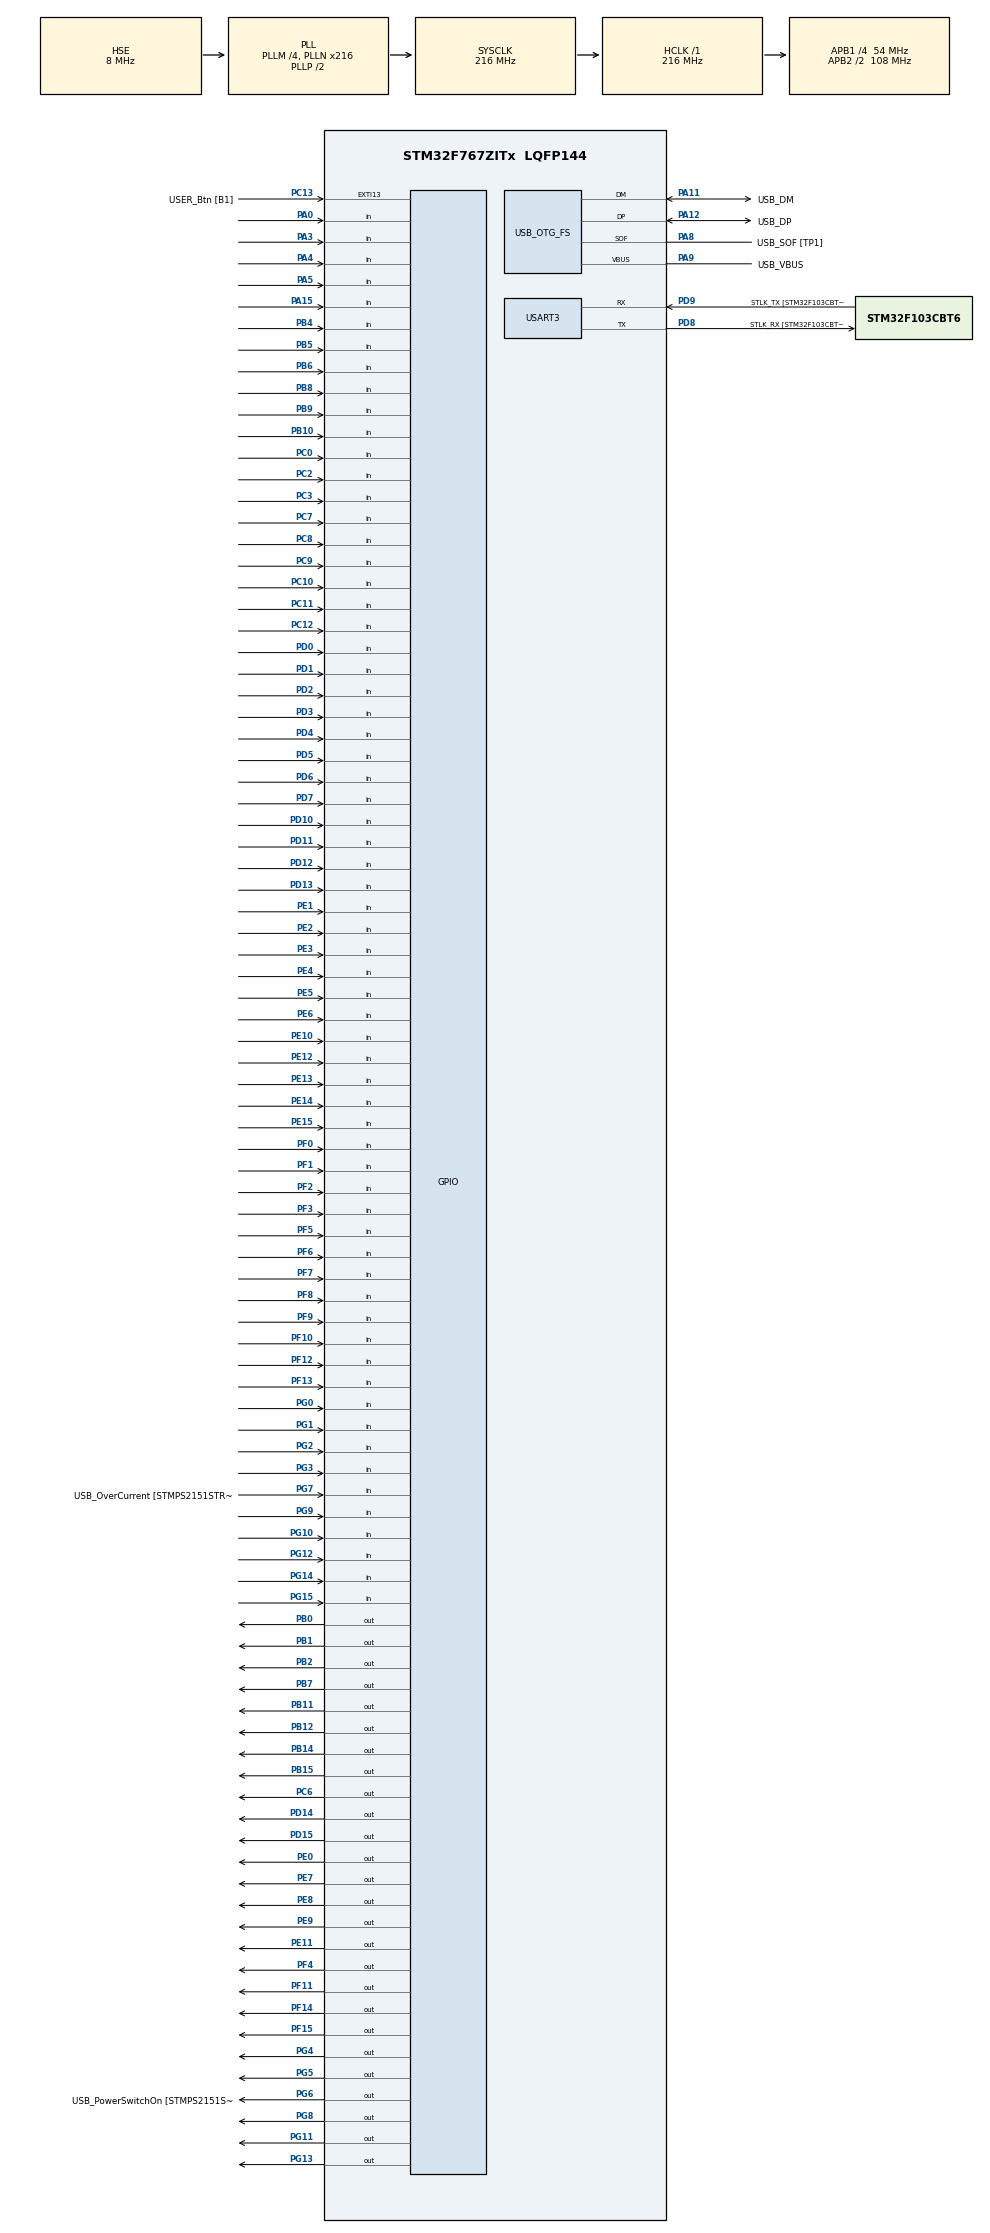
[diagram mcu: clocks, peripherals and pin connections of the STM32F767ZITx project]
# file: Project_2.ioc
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Mcu.Family=STM32F7
Mcu.Name=STM32F767ZITx
Mcu.Package=LQFP144
NVIC.PriorityGroup=NVIC_PRIORITYGROUP_2
NVIC.TIM3_IRQn=true\:1\:0\:true\:false\:true\:true\:true\:true
NVIC.TIM4_IRQn=true\:1\:0\:true\:false\:true\:true\:true\:true
PA0/WKUP.Signal=GPIO_Input
PA10.GPIO_Label=USB_ID
PA10.Signal=USB_OTG_FS_ID
PA11.GPIO_Label=USB_DM
PA11.Mode=Device_Only
PA11.Signal=USB_OTG_FS_DM
PA12.GPIO_Label=USB_DP
PA12.Mode=Device_Only
PA12.Signal=USB_OTG_FS_DP
PA13.GPIO_Label=TMS
PA13.Mode=Serial_Wire
PA13.Signal=SYS_JTMS-SWDIO
PA14.GPIO_Label=TCK
PA14.Mode=Serial_Wire
PA14.Signal=SYS_JTCK-SWCLK
PA15.Signal=GPIO_Input
PA3.Signal=GPIO_Input
PA4.Signal=GPIO_Input
PA5.Signal=GPIO_Input
PA8.GPIO_Label=USB_SOF [TP1]
PA8.Mode=Activate_SOF_FS
PA8.Signal=USB_OTG_FS_SOF
PA9.GPIO_Label=USB_VBUS
PA9.Mode=Activate_VBUS
PA9.Signal=USB_OTG_FS_VBUS
PB0.Signal=GPIO_Output
PB1.Signal=GPIO_Output
PB10.Signal=GPIO_Input
PB11.Signal=GPIO_Output
PB12.Signal=GPIO_Output
PB14.Signal=GPIO_Output
PB15.Signal=GPIO_Output
PB2.Signal=GPIO_Output
PB3.GPIO_Label=SWO
PB3.Signal=SYS_JTDO-SWO
PB4.Signal=GPIO_Input
PB5.Signal=GPIO_Input
PB6.Signal=GPIO_Input
PB7.Signal=GPIO_Output
PB8.Signal=GPIO_Input
PB9.Signal=GPIO_Input
PC0.Signal=GPIO_Input
PC10.Signal=GPIO_Input
PC11.Signal=GPIO_Input
PC12.Signal=GPIO_Input
PC13.GPIO_Label=USER_Btn [B1]
PC13.Signal=GPXTI13
PC14/OSC32_IN.Mode=LSE-External-Oscillator
PC14/OSC32_IN.Signal=RCC_OSC32_IN
PC15/OSC32_OUT.Mode=LSE-External-Oscillator
PC15/OSC32_OUT.Signal=RCC_OSC32_OUT
PC2.Signal=GPIO_Input
PC3.Signal=GPIO_Input
PC6.Signal=GPIO_Output
PC7.Signal=GPIO_Input
PC8.Signal=GPIO_Input
PC9.Signal=GPIO_Input
PD0.Signal=GPIO_Input
PD1.Signal=GPIO_Input
PD10.Signal=GPIO_Input
PD11.Signal=GPIO_Input
PD12.Signal=GPIO_Input
PD13.Signal=GPIO_Input
PD14.Signal=GPIO_Output
PD15.Signal=GPIO_Output
PD2.Signal=GPIO_Input
PD3.Signal=GPIO_Input
PD4.Signal=GPIO_Input
PD5.Signal=GPIO_Input
PD6.Signal=GPIO_Input
PD7.Signal=GPIO_Input
PD8.GPIO_Label=STLK_RX [STM32F103CBT6_PA3]
PD8.Mode=Asynchronous
PD8.Signal=USART3_TX
PD9.GPIO_Label=STLK_TX [STM32F103CBT6_PA2]
PD9.Mode=Asynchronous
PD9.Signal=USART3_RX
PE0.Signal=GPIO_Output
PE1.Signal=GPIO_Input
PE10.Signal=GPIO_Input
PE11.Signal=GPIO_Output
PE12.Signal=GPIO_Input
PE13.Signal=GPIO_Input
PE14.Signal=GPIO_Input
PE15.Signal=GPIO_Input
PE2.Signal=GPIO_Input
PE3.Signal=GPIO_Input
PE4.Signal=GPIO_Input
PE5.Signal=GPIO_Input
PE6.Signal=GPIO_Input
PE7.Signal=GPIO_Output
PE8.Signal=GPIO_Output
PE9.Signal=GPIO_Output
PF0.Signal=GPIO_Input
PF1.Signal=GPIO_Input
PF10.Signal=GPIO_Input
PF11.Signal=GPIO_Output
PF12.Signal=GPIO_Input
PF13.Signal=GPIO_Input
PF14.Signal=GPIO_Output
PF15.Signal=GPIO_Output
PF2.Signal=GPIO_Input
PF3.Signal=GPIO_Input
PF4.Signal=GPIO_Output
PF5.Signal=GPIO_Input
PF6.Signal=GPIO_Input
PF7.Signal=GPIO_Input
PF8.Signal=GPIO_Input
PF9.Signal=GPIO_Input
PG0.Signal=GPIO_Input
PG1.Signal=GPIO_Input
PG10.Signal=GPIO_Input
PG11.Signal=GPIO_Output
PG12.Signal=GPIO_Input
PG13.Signal=GPIO_Output
PG14.Signal=GPIO_Input
PG15.Signal=GPIO_Input
PG2.Signal=GPIO_Input
PG3.Signal=GPIO_Input
PG4.Signal=GPIO_Output
PG5.Signal=GPIO_Output
PG6.GPIO_Label=USB_PowerSwitchOn [STMPS2151STR_EN]
PG6.Signal=GPIO_Output
PG7.GPIO_Label=USB_OverCurrent [STMPS2151STR_FAULT]
PG7.Signal=GPIO_Input
PG8.Signal=GPIO_Output
PG9.Signal=GPIO_Input
PH0/OSC_IN.GPIO_Label=MCO [STM32F103CBT6_PA8]
PH0/OSC_IN.Mode=HSE-External-Clock-Source
PH0/OSC_IN.Signal=RCC_OSC_IN
PH1/OSC_OUT.Mode=HSE-External-Clock-Source
PH1/OSC_OUT.Signal=RCC_OSC_OUT
ProjectManager.HeapSize=0x200
ProjectManager.StackSize=0x400
ProjectManager.TargetToolchain=STM32CubeIDE
RCC.48MHZClocksFreq_Value=24000000
RCC.AHBFreq_Value=216000000
RCC.APB1CLKDivider=RCC_HCLK_DIV4
RCC.APB1Freq_Value=54000000
RCC.APB1TimFreq_Value=108000000
RCC.APB2CLKDivider=RCC_HCLK_DIV2
RCC.APB2Freq_Value=108000000
RCC.APB2TimFreq_Value=216000000
RCC.CortexFreq_Value=216000000
RCC.HCLKFreq_Value=216000000
RCC.HSE_VALUE=8000000
RCC.HSI_VALUE=16000000
RCC.PLLM=4
RCC.PLLMUL=RCC_PLL_MUL9
RCC.PLLN=216
RCC.PLLQ=9
RCC.PRESCALERUSB=RCC_USBCLKSOURCE_PLL_DIV1_5
RCC.SYSCLKFreq_VALUE=216000000
RCC.SYSCLKSource=RCC_SYSCLKSOURCE_PLLCLK
RCC.SYSCLKSourceVirtual=RCC_SYSCLKSOURCE_PLLCLK
RCC.USBFreq_Value=48000000
RCC.VCOOutputFreq_Value=432000000
TIM3.Period=10000-1
TIM3.Prescaler=6480-1
TIM4.Period=10000-1
TIM4.Prescaler=5400-1
USART3.VirtualMode-Asynchronous=VM_ASYNC
USB_OTG_FS.VirtualMode=Device_Only
VP_TIM3_VS_ClockSourceINT.Mode=Internal
VP_TIM4_VS_ClockSourceINT.Mode=Internal
board=NUCLEO-F767ZI

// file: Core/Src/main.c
/* USER CODE BEGIN Header */
/**
  ******************************************************************************
  * @file           : main.c
  * @brief          : Main program body
  ******************************************************************************
  * @attention
  *
  * Copyright (c) 2022 STMicroelectronics.
  * All rights reserved.
  *
  * This software is licensed under terms that can be found in the LICENSE file
  * in the root directory of this software component.
  * If no LICENSE file comes with this software, it is provided AS-IS.
  *
  ******************************************************************************
  */
/* USER CODE END Header */
#include "main.h"

/* USER CODE BEGIN Includes */
#include "stdio.h"
#include <stdbool.h>
/* USER CODE END Includes */

/* USER CODE BEGIN PD */
#define true 	1
#define false  	0

uint32_t CountTim4; 				//For Scan Board
uint32_t CountTim3_PrintCheck;		//Print Debug
//bool a4;
//bool a3;
//bool a2;
//bool a1;
//extern bool OldState[8][8];
//bool NewState[8][8];
//extern bool State[8][8];
//char str[100];

/* USER CODE END PD */

TIM_HandleTypeDef htim3;
TIM_HandleTypeDef htim4;

UART_HandleTypeDef huart3;

PCD_HandleTypeDef hpcd_USB_OTG_FS;

void SystemClock_Config(void);
static void MX_GPIO_Init(void);
static void MX_USART3_UART_Init(void);
static void MX_USB_OTG_FS_PCD_Init(void);
static void MX_TIM4_Init(void);
static void MX_TIM3_Init(void);

int main(void)
{
  /* USER CODE BEGIN 1 */
	bool readState[8][8]; // [row][col]

	bool round_player; // true = player_1, false = player_1
	extern uint8_t chess[2][8][8]; // chess[player_id][row][col] = type ;// 0 is null
	bool tableCanGo[8][8] = {{false, false, false, false, false, false, false, false},
							 {false, false, false, false, false, false, false, false},
							 {false, false, false, false, false, false, false, false},
							 {false, false, false, false, false, false, false, false},
							 {false, false, false, false, false, false, false, false},
							 {false, false, false, false, false, false, false, false},
							 {false, false, false, false, false, false, false, false},
							 {false, false, false, false, false, false, false, false}};

  /* USER CODE END 1 */

  /* MCU Configuration--------------------------------------------------------*/

  /* Reset of all peripherals, Initializes the Flash interface and the Systick. */
  HAL_Init();

  /* Configure the system clock */
  SystemClock_Config();

  /* Initialize all configured peripherals */
  MX_GPIO_Init();
  MX_USART3_UART_Init();
  MX_USB_OTG_FS_PCD_Init();
  MX_TIM4_Init();
  MX_TIM3_Init();
  /* USER CODE BEGIN 2 */

  HAL_TIM_Base_Start_IT(&htim4);
  HAL_TIM_Base_Start_IT(&htim3);

  //State[0][0] = 1;
//  State[7][0] = false;
//  State[6][0] = false;
//  State[5][0] = false;
//  State[4][0] = false;
//  State[3][0] = false;
//  State[2][0] = false;
//  State[1][0] = false;
//  State[0][0] = false;

  /* USER CODE END 2 */

  /* Infinite loop */
  while (1)
  {

    /* USER CODE BEGIN 3 */

//	 if(State[7][0] != NewState[7][0]) {OldState[7][0] = State[7][0]; State[7][0] = NewState[7][0];}
//	 if(State[6][0] != NewState[6][0]) {OldState[6][0] = State[6][0]; State[6][0] = NewState[6][0];}
//	 if(State[5][0] != NewState[5][0]) {OldState[5][0] = State[5][0]; State[5][0] = NewState[5][0];}
//	 if(State[4][0] != NewState[4][0]) {OldState[4][0] = State[4][0]; State[4][0] = NewState[4][0];}
//	 a4 = HAL_GPIO_ReadPin(GPIOF, GPIO_PIN_8);
//	 a3 = HAL_GPIO_ReadPin(GPIOF, GPIO_PIN_7);
//	 a2 = HAL_GPIO_ReadPin(GPIOF, GPIO_PIN_9);
//	 a1 = HAL_GPIO_ReadPin(GPIOG, GPIO_PIN_1);

//	if(a4 == 1)
//	{
//		HAL_GPIO_WritePin(GPIOB, GPIO_PIN_14, 1);
//	}
	//sprintf(str,"State = %d\n\r", State[0][0]);
	//HAL_UART_Transmit(&huart3, (uint32_t *)  str, strlen(str), 1000);

//	else if(a2 == 1)
//	{
//		HAL_GPIO_WritePin(GPIOB, GPIO_PIN_14, 0);
//	}

  }
  /* USER CODE END 3 */
}

void SystemClock_Config(void)
{
  RCC_OscInitTypeDef RCC_OscInitStruct = {0};
  RCC_ClkInitTypeDef RCC_ClkInitStruct = {0};

  /** Configure LSE Drive Capability
  */
  HAL_PWR_EnableBkUpAccess();

  /** Configure the main internal regulator output voltage
  */
  __HAL_RCC_PWR_CLK_ENABLE();
  __HAL_PWR_VOLTAGESCALING_CONFIG(PWR_REGULATOR_VOLTAGE_SCALE1);

  /** Initializes the RCC Oscillators according to the specified parameters
  * in the RCC_OscInitTypeDef structure.
  */
  RCC_OscInitStruct.OscillatorType = RCC_OSCILLATORTYPE_HSE;
  RCC_OscInitStruct.HSEState = RCC_HSE_BYPASS;
  RCC_OscInitStruct.PLL.PLLState = RCC_PLL_ON;
  RCC_OscInitStruct.PLL.PLLSource = RCC_PLLSOURCE_HSE;
  RCC_OscInitStruct.PLL.PLLM = 4;
  RCC_OscInitStruct.PLL.PLLN = 216;
  RCC_OscInitStruct.PLL.PLLP = RCC_PLLP_DIV2;
  RCC_OscInitStruct.PLL.PLLQ = 9;
  RCC_OscInitStruct.PLL.PLLR = 2;
  if (HAL_RCC_OscConfig(&RCC_OscInitStruct) != HAL_OK)
  {
    Error_Handler();
  }

  /** Activate the Over-Drive mode
  */
  if (HAL_PWREx_EnableOverDrive() != HAL_OK)
  {
    Error_Handler();
  }

  /** Initializes the CPU, AHB and APB buses clocks
  */
  RCC_ClkInitStruct.ClockType = RCC_CLOCKTYPE_HCLK|RCC_CLOCKTYPE_SYSCLK
                              |RCC_CLOCKTYPE_PCLK1|RCC_CLOCKTYPE_PCLK2;
  RCC_ClkInitStruct.SYSCLKSource = RCC_SYSCLKSOURCE_PLLCLK;
  RCC_ClkInitStruct.AHBCLKDivider = RCC_SYSCLK_DIV1;
  RCC_ClkInitStruct.APB1CLKDivider = RCC_HCLK_DIV4;
  RCC_ClkInitStruct.APB2CLKDivider = RCC_HCLK_DIV2;

  if (HAL_RCC_ClockConfig(&RCC_ClkInitStruct, FLASH_LATENCY_7) != HAL_OK)
  {
    Error_Handler();
  }
}

static void MX_TIM3_Init(void)
{

  TIM_ClockConfigTypeDef sClockSourceConfig = {0};
  TIM_MasterConfigTypeDef sMasterConfig = {0};

  htim3.Instance = TIM3;
  htim3.Init.Prescaler = 6480-1;
  htim3.Init.CounterMode = TIM_COUNTERMODE_UP;
  htim3.Init.Period = 10000-1;
  htim3.Init.ClockDivision = TIM_CLOCKDIVISION_DIV1;
  htim3.Init.AutoReloadPreload = TIM_AUTORELOAD_PRELOAD_DISABLE;
  if (HAL_TIM_Base_Init(&htim3) != HAL_OK)
  {
    Error_Handler();
  }
  sClockSourceConfig.ClockSource = TIM_CLOCKSOURCE_INTERNAL;
  if (HAL_TIM_ConfigClockSource(&htim3, &sClockSourceConfig) != HAL_OK)
  {
    Error_Handler();
  }
  sMasterConfig.MasterOutputTrigger = TIM_TRGO_RESET;
  sMasterConfig.MasterSlaveMode = TIM_MASTERSLAVEMODE_DISABLE;
  if (HAL_TIMEx_MasterConfigSynchronization(&htim3, &sMasterConfig) != HAL_OK)
  {
    Error_Handler();
  }

}

static void MX_TIM4_Init(void)
{

  TIM_ClockConfigTypeDef sClockSourceConfig = {0};
  TIM_MasterConfigTypeDef sMasterConfig = {0};

  htim4.Instance = TIM4;
  htim4.Init.Prescaler = 5400-1;
  htim4.Init.CounterMode = TIM_COUNTERMODE_UP;
  htim4.Init.Period = 10000-1;
  htim4.Init.ClockDivision = TIM_CLOCKDIVISION_DIV1;
  htim4.Init.AutoReloadPreload = TIM_AUTORELOAD_PRELOAD_DISABLE;
  if (HAL_TIM_Base_Init(&htim4) != HAL_OK)
  {
    Error_Handler();
  }
  sClockSourceConfig.ClockSource = TIM_CLOCKSOURCE_INTERNAL;
  if (HAL_TIM_ConfigClockSource(&htim4, &sClockSourceConfig) != HAL_OK)
  {
    Error_Handler();
  }
  sMasterConfig.MasterOutputTrigger = TIM_TRGO_RESET;
  sMasterConfig.MasterSlaveMode = TIM_MASTERSLAVEMODE_DISABLE;
  if (HAL_TIMEx_MasterConfigSynchronization(&htim4, &sMasterConfig) != HAL_OK)
  {
    Error_Handler();
  }

}

static void MX_USART3_UART_Init(void)
{

  huart3.Instance = USART3;
  huart3.Init.BaudRate = 115200;
  huart3.Init.WordLength = UART_WORDLENGTH_8B;
  huart3.Init.StopBits = UART_STOPBITS_1;
  huart3.Init.Parity = UART_PARITY_NONE;
  huart3.Init.Mode = UART_MODE_TX_RX;
  huart3.Init.HwFlowCtl = UART_HWCONTROL_NONE;
  huart3.Init.OverSampling = UART_OVERSAMPLING_16;
  huart3.Init.OneBitSampling = UART_ONE_BIT_SAMPLE_DISABLE;
  huart3.AdvancedInit.AdvFeatureInit = UART_ADVFEATURE_NO_INIT;
  if (HAL_UART_Init(&huart3) != HAL_OK)
  {
    Error_Handler();
  }

}

static void MX_USB_OTG_FS_PCD_Init(void)
{

  hpcd_USB_OTG_FS.Instance = USB_OTG_FS;
  hpcd_USB_OTG_FS.Init.dev_endpoints = 6;
  hpcd_USB_OTG_FS.Init.speed = PCD_SPEED_FULL;
  hpcd_USB_OTG_FS.Init.dma_enable = DISABLE;
  hpcd_USB_OTG_FS.Init.phy_itface = PCD_PHY_EMBEDDED;
  hpcd_USB_OTG_FS.Init.Sof_enable = ENABLE;
  hpcd_USB_OTG_FS.Init.low_power_enable = DISABLE;
  hpcd_USB_OTG_FS.Init.lpm_enable = DISABLE;
  hpcd_USB_OTG_FS.Init.vbus_sensing_enable = ENABLE;
  hpcd_USB_OTG_FS.Init.use_dedicated_ep1 = DISABLE;
  if (HAL_PCD_Init(&hpcd_USB_OTG_FS) != HAL_OK)
  {
    Error_Handler();
  }

}

static void MX_GPIO_Init(void)
{
  GPIO_InitTypeDef GPIO_InitStruct = {0};

  /* GPIO Ports Clock Enable */
  __HAL_RCC_GPIOE_CLK_ENABLE();
  __HAL_RCC_GPIOC_CLK_ENABLE();
  __HAL_RCC_GPIOF_CLK_ENABLE();
  __HAL_RCC_GPIOH_CLK_ENABLE();
  __HAL_RCC_GPIOA_CLK_ENABLE();
  __HAL_RCC_GPIOB_CLK_ENABLE();
  __HAL_RCC_GPIOG_CLK_ENABLE();
  __HAL_RCC_GPIOD_CLK_ENABLE();

  /*Configure GPIO pin Output Level */
  HAL_GPIO_WritePin(GPIOF, GPIO_PIN_4|GPIO_PIN_11|GPIO_PIN_14|GPIO_PIN_15, GPIO_PIN_RESET);

  /*Configure GPIO pin Output Level */
  HAL_GPIO_WritePin(GPIOB, GPIO_PIN_0|GPIO_PIN_1|GPIO_PIN_2|GPIO_PIN_11
                          |GPIO_PIN_12|GPIO_PIN_14|GPIO_PIN_15|GPIO_PIN_7, GPIO_PIN_RESET);

  /*Configure GPIO pin Output Level */
  HAL_GPIO_WritePin(GPIOE, GPIO_PIN_7|GPIO_PIN_8|GPIO_PIN_9|GPIO_PIN_11
                          |GPIO_PIN_0, GPIO_PIN_RESET);

  /*Configure GPIO pin Output Level */
  HAL_GPIO_WritePin(GPIOD, GPIO_PIN_14|GPIO_PIN_15, GPIO_PIN_RESET);

  /*Configure GPIO pin Output Level */
  HAL_GPIO_WritePin(GPIOG, GPIO_PIN_4|GPIO_PIN_5|USB_PowerSwitchOn_Pin|GPIO_PIN_8
                          |GPIO_PIN_11|GPIO_PIN_13, GPIO_PIN_RESET);

  /*Configure GPIO pin Output Level */
  HAL_GPIO_WritePin(GPIOC, GPIO_PIN_6, GPIO_PIN_RESET);

  /*Configure GPIO pins : PE2 PE3 PE4 PE5
                           PE6 PE10 PE12 PE13
                           PE14 PE15 PE1 */
  GPIO_InitStruct.Pin = GPIO_PIN_2|GPIO_PIN_3|GPIO_PIN_4|GPIO_PIN_5
                          |GPIO_PIN_6|GPIO_PIN_10|GPIO_PIN_12|GPIO_PIN_13
                          |GPIO_PIN_14|GPIO_PIN_15|GPIO_PIN_1;
  GPIO_InitStruct.Mode = GPIO_MODE_INPUT;
  GPIO_InitStruct.Pull = GPIO_NOPULL;
  HAL_GPIO_Init(GPIOE, &GPIO_InitStruct);

  /*Configure GPIO pin : USER_Btn_Pin */
  GPIO_InitStruct.Pin = USER_Btn_Pin;
  GPIO_InitStruct.Mode = GPIO_MODE_IT_RISING;
  GPIO_InitStruct.Pull = GPIO_NOPULL;
  HAL_GPIO_Init(USER_Btn_GPIO_Port, &GPIO_InitStruct);

  /*Configure GPIO pins : PF0 PF1 PF2 PF3
                           PF5 PF6 PF7 PF8
                           PF9 PF10 PF12 PF13 */
  GPIO_InitStruct.Pin = GPIO_PIN_0|GPIO_PIN_1|GPIO_PIN_2|GPIO_PIN_3
                          |GPIO_PIN_5|GPIO_PIN_6|GPIO_PIN_7|GPIO_PIN_8
                          |GPIO_PIN_9|GPIO_PIN_10|GPIO_PIN_12|GPIO_PIN_13;
  GPIO_InitStruct.Mode = GPIO_MODE_INPUT;
  GPIO_InitStruct.Pull = GPIO_NOPULL;
  HAL_GPIO_Init(GPIOF, &GPIO_InitStruct);

  /*Configure GPIO pins : PF4 PF11 PF14 PF15 */
  GPIO_InitStruct.Pin = GPIO_PIN_4|GPIO_PIN_11|GPIO_PIN_14|GPIO_PIN_15;
  GPIO_InitStruct.Mode = GPIO_MODE_OUTPUT_PP;
  GPIO_InitStruct.Pull = GPIO_NOPULL;
  GPIO_InitStruct.Speed = GPIO_SPEED_FREQ_LOW;
  HAL_GPIO_Init(GPIOF, &GPIO_InitStruct);

  /*Configure GPIO pins : PC0 PC2 PC3 PC7
                           PC8 PC9 PC10 PC11
                           PC12 */
  GPIO_InitStruct.Pin = GPIO_PIN_0|GPIO_PIN_2|GPIO_PIN_3|GPIO_PIN_7
                          |GPIO_PIN_8|GPIO_PIN_9|GPIO_PIN_10|GPIO_PIN_11
                          |GPIO_PIN_12;
  GPIO_InitStruct.Mode = GPIO_MODE_INPUT;
  GPIO_InitStruct.Pull = GPIO_NOPULL;
  HAL_GPIO_Init(GPIOC, &GPIO_InitStruct);

  /*Configure GPIO pins : PA0 PA3 PA4 PA5
                           PA15 */
  GPIO_InitStruct.Pin = GPIO_PIN_0|GPIO_PIN_3|GPIO_PIN_4|GPIO_PIN_5
                          |GPIO_PIN_15;
  GPIO_InitStruct.Mode = GPIO_MODE_INPUT;
  GPIO_InitStruct.Pull = GPIO_NOPULL;
  HAL_GPIO_Init(GPIOA, &GPIO_InitStruct);

  /*Configure GPIO pins : PB0 PB1 PB2 PB11
                           PB12 PB14 PB15 PB7 */
  GPIO_InitStruct.Pin = GPIO_PIN_0|GPIO_PIN_1|GPIO_PIN_2|GPIO_PIN_11
                          |GPIO_PIN_12|GPIO_PIN_14|GPIO_PIN_15|GPIO_PIN_7;
  GPIO_InitStruct.Mode = GPIO_MODE_OUTPUT_PP;
  GPIO_InitStruct.Pull = GPIO_NOPULL;
  GPIO_InitStruct.Speed = GPIO_SPEED_FREQ_LOW;
  HAL_GPIO_Init(GPIOB, &GPIO_InitStruct);

  /*Configure GPIO pins : PG0 PG1 PG2 PG3
                           USB_OverCurrent_Pin PG9 PG10 PG12
                           PG14 PG15 */
  GPIO_InitStruct.Pin = GPIO_PIN_0|GPIO_PIN_1|GPIO_PIN_2|GPIO_PIN_3
                          |USB_OverCurrent_Pin|GPIO_PIN_9|GPIO_PIN_10|GPIO_PIN_12
                          |GPIO_PIN_14|GPIO_PIN_15;
  GPIO_InitStruct.Mode = GPIO_MODE_INPUT;
  GPIO_InitStruct.Pull = GPIO_NOPULL;
  HAL_GPIO_Init(GPIOG, &GPIO_InitStruct);

  /*Configure GPIO pins : PE7 PE8 PE9 PE11
                           PE0 */
  GPIO_InitStruct.Pin = GPIO_PIN_7|GPIO_PIN_8|GPIO_PIN_9|GPIO_PIN_11
                          |GPIO_PIN_0;
  GPIO_InitStruct.Mode = GPIO_MODE_OUTPUT_PP;
  GPIO_InitStruct.Pull = GPIO_NOPULL;
  GPIO_InitStruct.Speed = GPIO_SPEED_FREQ_LOW;
  HAL_GPIO_Init(GPIOE, &GPIO_InitStruct);

  /*Configure GPIO pins : PB10 PB4 PB5 PB6
                           PB8 PB9 */
  GPIO_InitStruct.Pin = GPIO_PIN_10|GPIO_PIN_4|GPIO_PIN_5|GPIO_PIN_6
                          |GPIO_PIN_8|GPIO_PIN_9;
  GPIO_InitStruct.Mode = GPIO_MODE_INPUT;
  GPIO_InitStruct.Pull = GPIO_NOPULL;
  HAL_GPIO_Init(GPIOB, &GPIO_InitStruct);

  /*Configure GPIO pins : PD10 PD11 PD12 PD13
                           PD0 PD1 PD2 PD3
                           PD4 PD5 PD6 PD7 */
  GPIO_InitStruct.Pin = GPIO_PIN_10|GPIO_PIN_11|GPIO_PIN_12|GPIO_PIN_13
                          |GPIO_PIN_0|GPIO_PIN_1|GPIO_PIN_2|GPIO_PIN_3
                          |GPIO_PIN_4|GPIO_PIN_5|GPIO_PIN_6|GPIO_PIN_7;
  GPIO_InitStruct.Mode = GPIO_MODE_INPUT;
  GPIO_InitStruct.Pull = GPIO_NOPULL;
  HAL_GPIO_Init(GPIOD, &GPIO_InitStruct);

  /*Configure GPIO pins : PD14 PD15 */
  GPIO_InitStruct.Pin = GPIO_PIN_14|GPIO_PIN_15;
  GPIO_InitStruct.Mode = GPIO_MODE_OUTPUT_PP;
  GPIO_InitStruct.Pull = GPIO_NOPULL;
  GPIO_InitStruct.Speed = GPIO_SPEED_FREQ_LOW;
  HAL_GPIO_Init(GPIOD, &GPIO_InitStruct);

  /*Configure GPIO pins : PG4 PG5 USB_PowerSwitchOn_Pin PG8
                           PG11 PG13 */
  GPIO_InitStruct.Pin = GPIO_PIN_4|GPIO_PIN_5|USB_PowerSwitchOn_Pin|GPIO_PIN_8
                          |GPIO_PIN_11|GPIO_PIN_13;
  GPIO_InitStruct.Mode = GPIO_MODE_OUTPUT_PP;
  GPIO_InitStruct.Pull = GPIO_NOPULL;
  GPIO_InitStruct.Speed = GPIO_SPEED_FREQ_LOW;
  HAL_GPIO_Init(GPIOG, &GPIO_InitStruct);

  /*Configure GPIO pin : PC6 */
  GPIO_InitStruct.Pin = GPIO_PIN_6;
  GPIO_InitStruct.Mode = GPIO_MODE_OUTPUT_PP;
  GPIO_InitStruct.Pull = GPIO_NOPULL;
  GPIO_InitStruct.Speed = GPIO_SPEED_FREQ_LOW;
  HAL_GPIO_Init(GPIOC, &GPIO_InitStruct);

}

/* USER CODE BEGIN 4 */
//static bool checkWhereCanGo(bool round_player, uint8_t player_id, uint8_t row, uint8_t col, uint8_t type){
//	if(player_id != round_player){
//		return false; //wrong player playing
//	}
//	else{//true player playing
//		if(player_id == 0){ // above player
//			if(type == 1){ // beer
//				if(row != 0){
//					if(isEmpthy(row-1,col)){
//						tableCanGo[row-1][col] = true;
//					}
//					if(col>0 && col <=7 && isEnemy(round_player, round_player, row-1, col-1)){
//						tableCanGo[row-1][col-1] = true;
//					}
//					if(col>=0 && col <7 && isEnemy(round_player, round_player, row-1, col+1)){
//						tableCanGo[row-1][col+1] = true;
//					}
//				}
//				else { //change beer to beer ngai
//					type = 7;
//					chess[player_id][row][col] = 7;
//				}
//			}
//			else if (type == 2){ // boat
//				for(uint8_t i = 0; i < 8; i++){
//					if(isEmpthy(row, i) || isEnemy(round_player, round_player, row, i)){
//						tableCanGo[row][i] = true;
//					}
//					if(isEmpthy(i,col) || isEnemy(round_player, round_player, i, col)){
//						tableCanGo[i][col] = true;
//					}
//				}
//			}
//			else if (type == 3){ // horse
//				if()
//			}
//		}
//	}
//}
//
//static uint8_t isEnemy(uint8_t round_player, uint8_t player_id, uint8_t row, uint8_t col){
//	if (round_player != player_id && chess[player_id][row][col] > 0){
//		return true;
//	}
//	return false;
//}
//
//static bool isEmpthy(uint8_t row, uint8_t col){
//	if (chess[0][row][col] == 0 && chess[1][row][col] == 0){
//		return true;
//	}
//	return false;
//}

extern void displayNumber(uint32_t c)
{
	char buffer[100];
	//int time = c/1000;

//	sprintf(buffer,"count time %02d:%02d\r", time/60,time%60  );
	sprintf(buffer,"count time :%2d\n\r", c);
	HAL_UART_Transmit(&huart3, (uint32_t *) buffer, strlen(buffer), 1000);
}

//========================== DisPlay State [4][4] ======================================//
extern void displayOld_State(bool a4, bool a3, bool a2, bool a1)
{
	char buffer[100];

	sprintf(buffer,"OldState: \t%d\n\r\t\t%d\n\r\t\t%d\n\r\t\t%d\n\r-----------------------\n\r", a4, a3, a2, a1);
	HAL_UART_Transmit(&huart3, (uint32_t *) buffer, strlen(buffer), 1000);
}

//========================== DisPlay New State [4][4] ======================================//
extern void displayNew_State(bool a4, bool a3, bool a2, bool a1)
{
	char buffer[100];

	sprintf(buffer,"NewState: \t%d\n\r\t\t%d\n\r\t\t%d\n\r\t\t%d\n\r=======================\n\r", a4, a3, a2, a1);
	HAL_UART_Transmit(&huart3, (uint32_t *) buffer, strlen(buffer), 1000);
}

/* USER CODE END 4 */

void Error_Handler(void)
{
  __disable_irq();
  while (1)
  {
  }
}
